AUTOSAR XML (schema 00046)
package /ComponentTypes
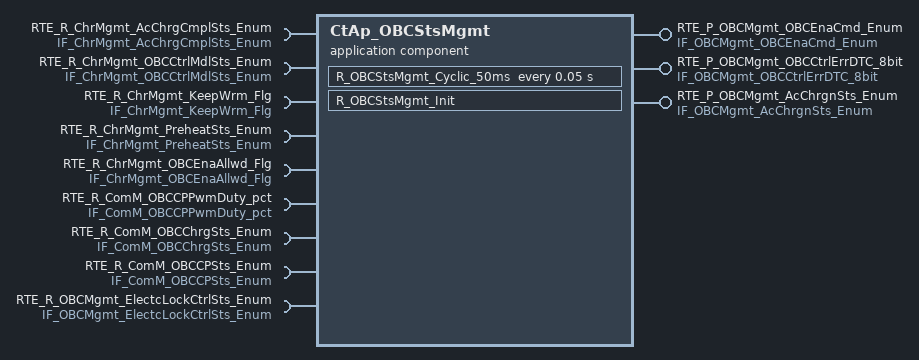
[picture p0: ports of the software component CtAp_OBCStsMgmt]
  application sw component type CtAp_OBCStsMgmt
    provide port RTE_P_OBCMgmt_OBCEnaCmd_Enum: nonqueued-sender-com-spec{data-element=tec_OBCMgmt_OBCEnaCmd_Enum, init-value=0}, provided-interface=IF_OBCMgmt_OBCEnaCmd_Enum
    provide port RTE_P_OBCMgmt_OBCCtrlErrDTC_8bit: nonqueued-sender-com-spec{data-element=tec_OBCMgmt_OBCCtrlErrDTC_8bit, init-value=0}, provided-interface=IF_OBCMgmt_OBCCtrlErrDTC_8bit
    9 x require port:
      RTE_R_ChrMgmt_AcChrgCmplSts_Enum: nonqueued-receiver-com-spec{data-element=tec_ChrMgmt_AcChrgCmplSts_Enum, filter=data-filter-type=ALWAYS, init-value=0}, required-interface=IF_ChrMgmt_AcChrgCmplSts_Enum
      RTE_R_ChrMgmt_OBCCtrlMdlSts_Enum: nonqueued-receiver-com-spec{data-element=tec_ChrMgmt_OBCCtrlMdlSts_Enum, filter=data-filter-type=ALWAYS, init-value=0}, required-interface=IF_ChrMgmt_OBCCtrlMdlSts_Enum
      RTE_R_ChrMgmt_KeepWrm_Flg: nonqueued-receiver-com-spec{data-element=tec_ChrMgmt_KeepWrm_Flg, filter=data-filter-type=ALWAYS, init-value=0}, required-interface=IF_ChrMgmt_KeepWrm_Flg
      RTE_R_ChrMgmt_PreheatSts_Enum: nonqueued-receiver-com-spec{data-element=tec_ChrMgmt_PreheatSts_Enum, filter=data-filter-type=ALWAYS, init-value=0}, required-interface=IF_ChrMgmt_PreheatSts_Enum
      RTE_R_ChrMgmt_OBCEnaAllwd_Flg: nonqueued-receiver-com-spec{data-element=tec_ChrMgmt_OBCEnaAllwd_Flg, filter=data-filter-type=ALWAYS, init-value=0}, required-interface=IF_ChrMgmt_OBCEnaAllwd_Flg
      RTE_R_ComM_OBCCPPwmDuty_pct: nonqueued-receiver-com-spec{data-element=tec_ComM_OBCCPPwmDuty_pct, filter=data-filter-type=ALWAYS, init-value=0}, required-interface=IF_ComM_OBCCPPwmDuty_pct
      RTE_R_ComM_OBCChrgSts_Enum: nonqueued-receiver-com-spec{data-element=tec_ComM_OBCChrgSts_Enum, filter=data-filter-type=ALWAYS, init-value=0}, required-interface=IF_ComM_OBCChrgSts_Enum
      RTE_R_ComM_OBCCPSts_Enum: nonqueued-receiver-com-spec{data-element=tec_ComM_OBCCPSts_Enum, filter=data-filter-type=ALWAYS, init-value=0}, required-interface=IF_ComM_OBCCPSts_Enum
      RTE_R_OBCMgmt_ElectcLockCtrlSts_Enum: nonqueued-receiver-com-spec{data-element=tec_OBCMgmt_ElectcLockCtrlSts_Enum, filter=data-filter-type=ALWAYS, init-value=0}, required-interface=IF_OBCMgmt_ElectcLockCtrlSts_Enum
    provide port RTE_P_OBCMgmt_AcChrgnSts_Enum: nonqueued-sender-com-spec{data-element=tec_OBCMgmt_AcChrgnSts_Enum, init-value=0}, provided-interface=IF_OBCMgmt_AcChrgnSts_Enum
    behavior CtAp_OBCStsMgmt_InternalBehavior
      init event CtAp_OBCStsMgmt_InitEvent: start-on-event=R_OBCStsMgmt_Init
      timing event TMT_R_OBCStsMgmt_Cyclic_50ms: start-on-event=R_OBCStsMgmt_Cyclic_50ms, period=0.05
      runnable R_OBCStsMgmt_Init
      runnable R_OBCStsMgmt_Cyclic_50ms
        data-receive-point-by-arguments:
          9 x access:
            REC_RTE_R_ChrMgmt_AcChrgCmplSts_Enum_tec_ChrMgmt_AcChrgCmplSts_Enum: accessed-variable=RTE_R_ChrMgmt_AcChrgCmplSts_Enum.tec_ChrMgmt_AcChrgCmplSts_Enum
            REC_RTE_R_ChrMgmt_KeepWrm_Flg_tec_ChrMgmt_KeepWrm_Flg: accessed-variable=RTE_R_ChrMgmt_KeepWrm_Flg.tec_ChrMgmt_KeepWrm_Flg
            REC_RTE_R_ChrMgmt_OBCCtrlMdlSts_Enum_tec_ChrMgmt_OBCCtrlMdlSts_Enum: accessed-variable=RTE_R_ChrMgmt_OBCCtrlMdlSts_Enum.tec_ChrMgmt_OBCCtrlMdlSts_Enum
            REC_RTE_R_ChrMgmt_OBCEnaAllwd_Flg_tec_ChrMgmt_OBCEnaAllwd_Flg: accessed-variable=RTE_R_ChrMgmt_OBCEnaAllwd_Flg.tec_ChrMgmt_OBCEnaAllwd_Flg
            REC_RTE_R_ChrMgmt_PreheatSts_Enum_tec_ChrMgmt_PreheatSts_Enum: accessed-variable=RTE_R_ChrMgmt_PreheatSts_Enum.tec_ChrMgmt_PreheatSts_Enum
            REC_RTE_R_ComM_OBCCPPwmDuty_pct_tec_ComM_OBCCPPwmDuty_pct: accessed-variable=RTE_R_ComM_OBCCPPwmDuty_pct.tec_ComM_OBCCPPwmDuty_pct
            REC_RTE_R_ComM_OBCCPSts_Enum_tec_ComM_OBCCPSts_Enum: accessed-variable=RTE_R_ComM_OBCCPSts_Enum.tec_ComM_OBCCPSts_Enum
            REC_RTE_R_ComM_OBCChrgSts_Enum_tec_ComM_OBCChrgSts_Enum: accessed-variable=RTE_R_ComM_OBCChrgSts_Enum.tec_ComM_OBCChrgSts_Enum
            REC_RTE_R_OBCMgmt_ElectcLockCtrlSts_Enum_tec_OBCMgmt_ElectcLockCtrlSts_Enum: accessed-variable=RTE_R_OBCMgmt_ElectcLockCtrlSts_Enum.tec_OBCMgmt_ElectcLockCtrlSts_Enum
        data-send-points:
          access SEND_RTE_P_OBCMgmt_OBCCtrlErrDTC_8bit_tec_OBCMgmt_OBCCtrlErrDTC_8bit: accessed-variable=RTE_P_OBCMgmt_OBCCtrlErrDTC_8bit.tec_OBCMgmt_OBCCtrlErrDTC_8bit
          access SEND_RTE_P_OBCMgmt_OBCEnaCmd_Enum_tec_OBCMgmt_OBCEnaCmd_Enum: accessed-variable=RTE_P_OBCMgmt_OBCEnaCmd_Enum.tec_OBCMgmt_OBCEnaCmd_Enum
          access SEND_RTE_P_OBCMgmt_AcChrgnSts_Enum_tec_OBCMgmt_AcChrgnSts_Enum: accessed-variable=RTE_P_OBCMgmt_AcChrgnSts_Enum.tec_OBCMgmt_AcChrgnSts_Enum
  swc implementation CtAp_OBCStsMgmt_Implementation: behavior=CtAp_OBCStsMgmt_InternalBehavior
    code-descriptors:
      code Default: artifact-descriptors=autosar-engineering-object=category=SWOBJ
